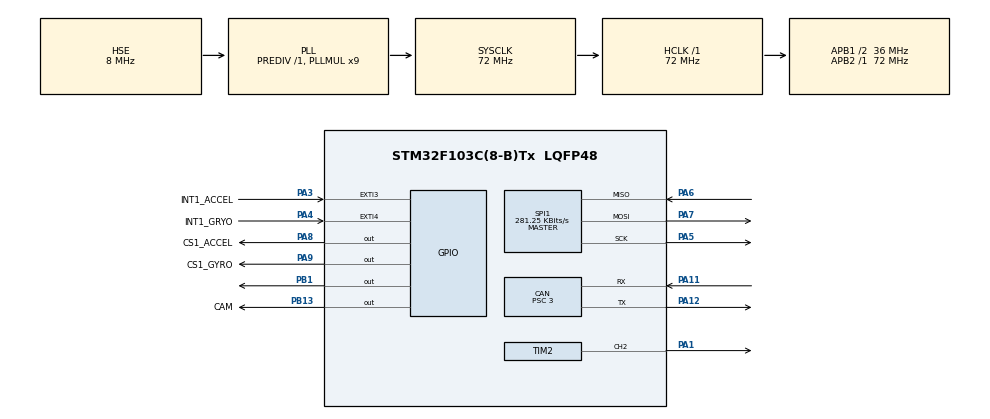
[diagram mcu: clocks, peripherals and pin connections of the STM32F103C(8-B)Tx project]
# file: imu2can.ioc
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CAN.BS1=CAN_BS1_7TQ
CAN.BS2=CAN_BS2_4TQ
CAN.CalculateBaudRate=999999
CAN.CalculateTimeBit=1000
CAN.CalculateTimeQuantum=83.33333333333334
CAN.Prescaler=3
Dma.Request0=SPI1_RX
Dma.Request1=SPI1_TX
Dma.SPI1_RX.0.Direction=DMA_PERIPH_TO_MEMORY
Dma.SPI1_RX.0.Instance=DMA1_Channel2
Dma.SPI1_RX.0.MemDataAlignment=DMA_MDATAALIGN_BYTE
Dma.SPI1_RX.0.MemInc=DMA_MINC_ENABLE
Dma.SPI1_RX.0.Mode=DMA_NORMAL
Dma.SPI1_RX.0.PeriphDataAlignment=DMA_PDATAALIGN_BYTE
Dma.SPI1_RX.0.PeriphInc=DMA_PINC_DISABLE
Dma.SPI1_RX.0.Priority=DMA_PRIORITY_VERY_HIGH
Dma.SPI1_TX.1.Direction=DMA_MEMORY_TO_PERIPH
Dma.SPI1_TX.1.Instance=DMA1_Channel3
Dma.SPI1_TX.1.MemDataAlignment=DMA_MDATAALIGN_BYTE
Dma.SPI1_TX.1.MemInc=DMA_MINC_ENABLE
Dma.SPI1_TX.1.Mode=DMA_NORMAL
Dma.SPI1_TX.1.PeriphDataAlignment=DMA_PDATAALIGN_BYTE
Dma.SPI1_TX.1.PeriphInc=DMA_PINC_DISABLE
Dma.SPI1_TX.1.Priority=DMA_PRIORITY_HIGH
Mcu.Family=STM32F1
Mcu.Name=STM32F103C(8-B)Tx
Mcu.Package=LQFP48
NVIC.CAN1_RX1_IRQn=true\:0\:0\:false\:false\:true\:true\:true\:true
NVIC.DMA1_Channel2_IRQn=true\:5\:0\:true\:false\:true\:false\:true\:true
NVIC.DMA1_Channel3_IRQn=true\:0\:0\:false\:false\:true\:false\:true\:true
NVIC.EXTI3_IRQn=true\:0\:0\:false\:false\:true\:true\:true\:true
NVIC.EXTI4_IRQn=true\:0\:0\:false\:false\:true\:true\:true\:true
NVIC.PriorityGroup=NVIC_PRIORITYGROUP_4
NVIC.USB_LP_CAN1_RX0_IRQn=true\:0\:0\:false\:false\:true\:true\:true\:true
PA1.Signal=S_TIM2_CH2
PA11.Mode=CAN_Activate
PA11.Signal=CAN_RX
PA12.Mode=CAN_Activate
PA12.Signal=CAN_TX
PA13.Mode=Serial_Wire
PA13.Signal=SYS_JTMS-SWDIO
PA14.Mode=Serial_Wire
PA14.Signal=SYS_JTCK-SWCLK
PA3.GPIO_Label=INT1_ACCEL
PA3.GPIO_ModeDefaultEXTI=GPIO_MODE_IT_FALLING
PA3.GPIO_PuPd=GPIO_PULLUP
PA3.Signal=GPXTI3
PA4.GPIO_Label=INT1_GRYO
PA4.GPIO_ModeDefaultEXTI=GPIO_MODE_IT_FALLING
PA4.GPIO_PuPd=GPIO_PULLUP
PA4.Signal=GPXTI4
PA5.Mode=Full_Duplex_Master
PA5.Signal=SPI1_SCK
PA6.Mode=Full_Duplex_Master
PA6.Signal=SPI1_MISO
PA7.Mode=Full_Duplex_Master
PA7.Signal=SPI1_MOSI
PA8.GPIO_Label=CS1_ACCEL
PA8.GPIO_PuPd=GPIO_PULLUP
PA8.GPIO_Speed=GPIO_SPEED_FREQ_HIGH
PA8.PinState=GPIO_PIN_SET
PA8.Signal=GPIO_Output
PA9.GPIO_Label=CS1_GYRO
PA9.GPIO_PuPd=GPIO_PULLUP
PA9.GPIO_Speed=GPIO_SPEED_FREQ_HIGH
PA9.PinState=GPIO_PIN_SET
PA9.Signal=GPIO_Output
PB1.GPIO_PuPd=GPIO_PULLUP
PB1.GPIO_Speed=GPIO_SPEED_FREQ_HIGH
PB1.Signal=GPIO_Output
PB13.GPIO_Label=CAM
PB13.GPIO_PuPd=GPIO_PULLUP
PB13.GPIO_Speed=GPIO_SPEED_FREQ_HIGH
PB13.PinState=GPIO_PIN_SET
PB13.Signal=GPIO_Output
PD0-OSC_IN.Mode=HSE-External-Oscillator
PD0-OSC_IN.Signal=RCC_OSC_IN
PD1-OSC_OUT.Mode=HSE-External-Oscillator
PD1-OSC_OUT.Signal=RCC_OSC_OUT
ProjectManager.HeapSize=0x200
ProjectManager.StackSize=0x400
ProjectManager.TargetToolchain=SW4STM32
RCC.AHBFreq_Value=72000000
RCC.APB1CLKDivider=RCC_HCLK_DIV2
RCC.APB1Freq_Value=36000000
RCC.APB1TimFreq_Value=72000000
RCC.APB2Freq_Value=72000000
RCC.APB2TimFreq_Value=72000000
RCC.HCLKFreq_Value=72000000
RCC.PLLMUL=RCC_PLL_MUL9
RCC.PLLSourceVirtual=RCC_PLLSOURCE_HSE
RCC.SYSCLKFreq_VALUE=72000000
RCC.SYSCLKSource=RCC_SYSCLKSOURCE_PLLCLK
RCC.USBFreq_Value=72000000
SH.S_TIM2_CH2.0=TIM2_CH2,PWM Generation2 CH2
SPI1.BaudRatePrescaler=SPI_BAUDRATEPRESCALER_256
SPI1.CLKPhase=SPI_PHASE_2EDGE
SPI1.CLKPolarity=SPI_POLARITY_HIGH
SPI1.CalculateBaudRate=281.25 KBits/s
SPI1.Direction=SPI_DIRECTION_2LINES
SPI1.Mode=SPI_MODE_MASTER
SPI1.VirtualType=VM_MASTER
TIM2.Channel-PWM\ Generation2\ CH2=TIM_CHANNEL_2
TIM2.Period=4999
VP_TIM2_VS_ClockSourceINT.Mode=Internal
board=custom

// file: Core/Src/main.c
/* USER CODE BEGIN Header */
/**
  ******************************************************************************
  * @file           : main.c
  * @brief          : Main program body
  ******************************************************************************
  * @attention
  *
  * <h2><center>&copy; Copyright (c) 2021 STMicroelectronics.
  * All rights reserved.</center></h2>
  *
  * This software component is licensed by ST under BSD 3-Clause license,
  * the "License"; You may not use this file except in compliance with the
  * License. You may obtain a copy of the License at:
  *                        opensource.org/licenses/BSD-3-Clause
  *
  ******************************************************************************
  */
/* USER CODE END Header */
#include "main.h"
#include "can.h"
#include "dma.h"
#include "spi.h"
#include "tim.h"
#include "gpio.h"

/* USER CODE BEGIN Includes */
#include "bsp_can.h"
#include "bsp_delay.h"
#include "imu_interrupt.h"
#include "imu_pwm.h"
/* USER CODE END Includes */

/* USER CODE BEGIN PV */
static CAN_TxHeaderTypeDef can_header;
static uint8_t can_data[8];
/* USER CODE END PV */

void SystemClock_Config(void);

int main(void)
{

  /* MCU Configuration--------------------------------------------------------*/

  /* Reset of all peripherals, Initializes the Flash interface and the Systick. */
  HAL_Init();

  /* Configure the system clock */
  SystemClock_Config();

  /* Initialize all configured peripherals */
  MX_GPIO_Init();
  MX_DMA_Init();
  MX_CAN_Init();
  MX_SPI1_Init();
  MX_TIM2_Init();
  /* USER CODE BEGIN 2 */
  can_init();
  delay_init();
  imu_interrupt_init();
  imu_pwm_set(0);
  HAL_TIM_PWM_Start(&htim2, TIM_CHANNEL_2);
  HAL_GPIO_WritePin(CAM_GPIO_Port, CAM_Pin, GPIO_PIN_RESET);
  HAL_GPIO_WritePin(GPIOB, GPIO_PIN_1, GPIO_PIN_SET);

  /* USER CODE END 2 */
  /* Infinite loop */
  while (1) {

  }
}

void SystemClock_Config(void)
{
  RCC_OscInitTypeDef RCC_OscInitStruct = {0};
  RCC_ClkInitTypeDef RCC_ClkInitStruct = {0};

  /** Initializes the RCC Oscillators according to the specified parameters
  * in the RCC_OscInitTypeDef structure.
  */
  RCC_OscInitStruct.OscillatorType = RCC_OSCILLATORTYPE_HSE;
  RCC_OscInitStruct.HSEState = RCC_HSE_ON;
  RCC_OscInitStruct.HSEPredivValue = RCC_HSE_PREDIV_DIV1;
  RCC_OscInitStruct.HSIState = RCC_HSI_ON;
  RCC_OscInitStruct.PLL.PLLState = RCC_PLL_ON;
  RCC_OscInitStruct.PLL.PLLSource = RCC_PLLSOURCE_HSE;
  RCC_OscInitStruct.PLL.PLLMUL = RCC_PLL_MUL9;
  if (HAL_RCC_OscConfig(&RCC_OscInitStruct) != HAL_OK)
  {
    Error_Handler();
  }

  /** Initializes the CPU, AHB and APB buses clocks
  */
  RCC_ClkInitStruct.ClockType = RCC_CLOCKTYPE_HCLK|RCC_CLOCKTYPE_SYSCLK
                              |RCC_CLOCKTYPE_PCLK1|RCC_CLOCKTYPE_PCLK2;
  RCC_ClkInitStruct.SYSCLKSource = RCC_SYSCLKSOURCE_PLLCLK;
  RCC_ClkInitStruct.AHBCLKDivider = RCC_SYSCLK_DIV1;
  RCC_ClkInitStruct.APB1CLKDivider = RCC_HCLK_DIV2;
  RCC_ClkInitStruct.APB2CLKDivider = RCC_HCLK_DIV1;

  if (HAL_RCC_ClockConfig(&RCC_ClkInitStruct, FLASH_LATENCY_2) != HAL_OK)
  {
    Error_Handler();
  }
}

void Error_Handler(void)
{
  __disable_irq();
  while (1)
  {
  }
}
